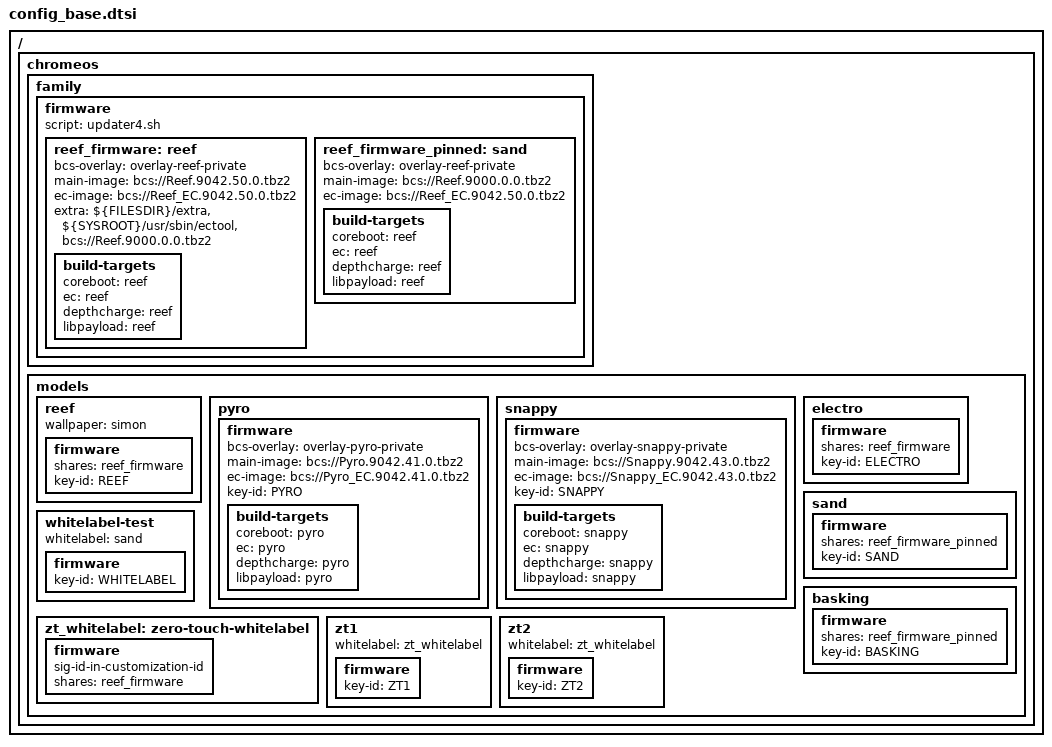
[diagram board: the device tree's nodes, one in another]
/ {
    chromeos {
        family {
            firmware {
                script = "updater4.sh";
                reef_firmware: reef {
                    bcs-overlay = "overlay-reef-private";
                    main-image = "bcs://Reef.9042.50.0.tbz2";
                    ec-image = "bcs://Reef_EC.9042.50.0.tbz2";
                    extra = "${FILESDIR}/extra", "${SYSROOT}/usr/sbin/ectool", "bcs://Reef.9000.0.0.tbz2";
                    build-targets {
                        coreboot = "reef";
                        ec = "reef";
                        depthcharge = "reef";
                        libpayload = "reef";
                    };
                };

                reef_firmware_pinned: sand {
                    bcs-overlay = "overlay-reef-private";
                    main-image = "bcs://Reef.9000.0.0.tbz2";
                    ec-image = "bcs://Reef_EC.9042.50.0.tbz2";
                    build-targets {
                        coreboot = "reef";
                        ec = "reef";
                        depthcharge = "reef";
                        libpayload = "reef";
                    };
                };
            };
        };

        models: models {
            reef {
                wallpaper = "simon";
                firmware {
                    shares = <&reef_firmware>;
                    key-id = "REEF";
                };
            };
            pyro {
                firmware {
                    bcs-overlay = "overlay-pyro-private";
                    main-image = "bcs://Pyro.9042.41.0.tbz2";
                    ec-image = "bcs://Pyro_EC.9042.41.0.tbz2";
                    key-id = "PYRO";
                    build-targets {
                        coreboot = "pyro";
                        ec = "pyro";
                        depthcharge = "pyro";
                        libpayload = "pyro";
                    };
                };
            };
            snappy {
                firmware {
                    bcs-overlay = "overlay-snappy-private";
                    main-image = "bcs://Snappy.9042.43.0.tbz2";
                    ec-image = "bcs://Snappy_EC.9042.43.0.tbz2";
                    key-id = "SNAPPY";
                    build-targets {
                        coreboot = "snappy";
                        ec = "snappy";
                        depthcharge = "snappy";
                        libpayload = "snappy";
                    };
                };
            };
            electro {
                firmware {
                    shares = <&reef_firmware>;
                    key-id = "ELECTRO";
                };
            };
            sand: sand {
                firmware {
                    shares = <&reef_firmware_pinned>;
                    key-id = "SAND";
                };
            };
            basking {
                firmware {
                    shares = <&reef_firmware_pinned>;
                    key-id = "BASKING";
                };
            };
            whitelabel-test {
                whitelabel = <&sand>;
                firmware {
                    key-id = "WHITELABEL";
                };
            };
            zt_whitelabel: zero-touch-whitelabel {
                firmware {
                    sig-id-in-customization-id;
                    shares = <&reef_firmware>;
                };
            };
            zt1 {
                whitelabel = <&zt_whitelabel>;
                firmware {
                    key-id = "ZT1";
                };
            };
            zt2 {
                whitelabel = <&zt_whitelabel>;
                firmware {
                    key-id = "ZT2";
                };
            };
        };
    };
};
